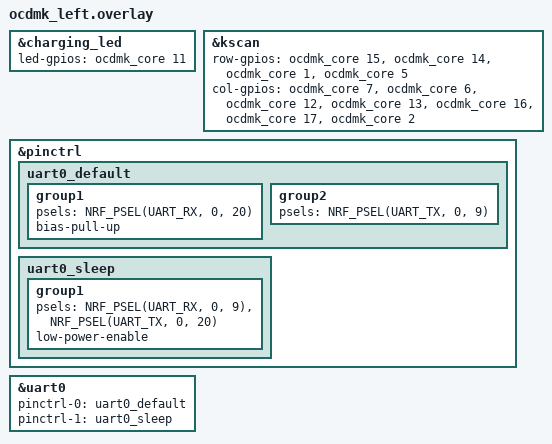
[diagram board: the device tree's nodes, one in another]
/*
 * OCDMK Left Shield Overlay
 */

#include "ocdmk.dtsi"

/* Charging LED output for left side */
&charging_led {
    led-gpios = <&ocdmk_core 11 GPIO_ACTIVE_HIGH>;  /* Pin 1: P0.15 */
};

&kscan {
    /*
     * Row pins (left side - mirrored connector)
     * Rows are OUTPUTS (driven high) for row2col diode direction
     */
    row-gpios
        = <&ocdmk_core 15 GPIO_ACTIVE_HIGH>  /* R1: P0.01 (was Pin5) */
        , <&ocdmk_core 14 GPIO_ACTIVE_HIGH>  /* R2: P0.04 (was Pin4) */
        , <&ocdmk_core 1 GPIO_ACTIVE_HIGH>   /* R3: P0.15 (was Pin11) */
        , <&ocdmk_core 5 GPIO_ACTIVE_HIGH>   /* R4: P0.10 (was Pin15) */
        ;

    /*
     * Column pins (left side - original order starting with pin 17)
     * Columns are INPUTS (with pull-down) for row2col diode direction
     */
    col-gpios
        = <&ocdmk_core 7 (GPIO_ACTIVE_HIGH | GPIO_PULL_DOWN)>  /* C0: P0.29 (Pin17) */
        , <&ocdmk_core 6 (GPIO_ACTIVE_HIGH | GPIO_PULL_DOWN)>  /* C1: P0.28 (Pin16) */
        , <&ocdmk_core 12 (GPIO_ACTIVE_HIGH | GPIO_PULL_DOWN)>   /* C2: P0.17 (Pin2) */
        , <&ocdmk_core 13 (GPIO_ACTIVE_HIGH | GPIO_PULL_DOWN)>   /* C3: P0.20 (Pin3) */
        , <&ocdmk_core 16 (GPIO_ACTIVE_HIGH | GPIO_PULL_DOWN)>   /* C4: P0.03 (Pin6) */
        , <&ocdmk_core 17 (GPIO_ACTIVE_HIGH | GPIO_PULL_DOWN)>   /* C5: P0.02 (Pin7) */
        , <&ocdmk_core 2 (GPIO_ACTIVE_HIGH | GPIO_PULL_DOWN)>  /* C6: P1.09 (Pin12) */
        ;
};

/*
 * UART wired split — left (central): connector pins 3 / 4 → P0.20 (RX) / P0.09 (TX)
 * Cable crossover: Left pin 3 (TX=P0.20) → Right pin 13 (RX=P0.05);
 *                 Left pin 4 (RX=P0.09) → Right pin 14 (TX=P0.04).
 * Only included for wired builds (CONFIG_ZMK_BLE not set).
 */
#if !defined(CONFIG_ZMK_BLE)
&pinctrl {
    uart0_default: uart0_default {
        group1 {
            psels = <NRF_PSEL(UART_RX, 0, 20)>;
            bias-pull-up;
        };
        group2 {
            psels = <NRF_PSEL(UART_TX, 0, 9)>;
        };
    };

    uart0_sleep: uart0_sleep {
        group1 {
            psels = <NRF_PSEL(UART_RX, 0, 9)>,
                    <NRF_PSEL(UART_TX, 0, 20)>;
            low-power-enable;
        };
    };
};

&uart0 {
    status = "okay";
    pinctrl-0 = <&uart0_default>;
    pinctrl-1 = <&uart0_sleep>;
    pinctrl-names = "default", "sleep";
};
#endif
